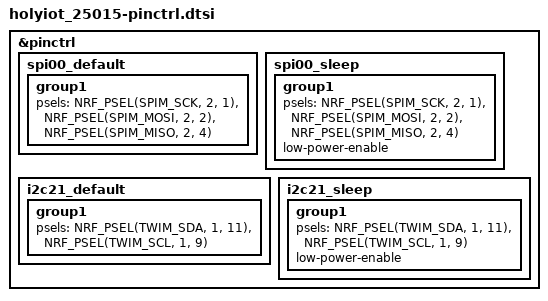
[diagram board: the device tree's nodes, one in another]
&pinctrl {
	/omit-if-no-ref/ spi00_default: spi00_default {
		group1 {
			psels = <NRF_PSEL(SPIM_SCK, 2, 1)>,
				<NRF_PSEL(SPIM_MOSI, 2, 2)>,
				<NRF_PSEL(SPIM_MISO, 2, 4)>;
		};
	};

	/omit-if-no-ref/ spi00_sleep: spi00_sleep {
		group1 {
			psels = <NRF_PSEL(SPIM_SCK, 2, 1)>,
				<NRF_PSEL(SPIM_MOSI, 2, 2)>,
				<NRF_PSEL(SPIM_MISO, 2, 4)>;
			low-power-enable;
		};
	};

	/omit-if-no-ref/ i2c21_default: i2c21_default {
		group1 {
			psels = <NRF_PSEL(TWIM_SDA, 1, 11)>,
				<NRF_PSEL(TWIM_SCL, 1, 9)>;
		};
	};

	/omit-if-no-ref/ i2c21_sleep: i2c21_sleep {
		group1 {
			psels = <NRF_PSEL(TWIM_SDA, 1, 11)>,
				<NRF_PSEL(TWIM_SCL, 1, 9)>;
			low-power-enable;
		};
	};
};
